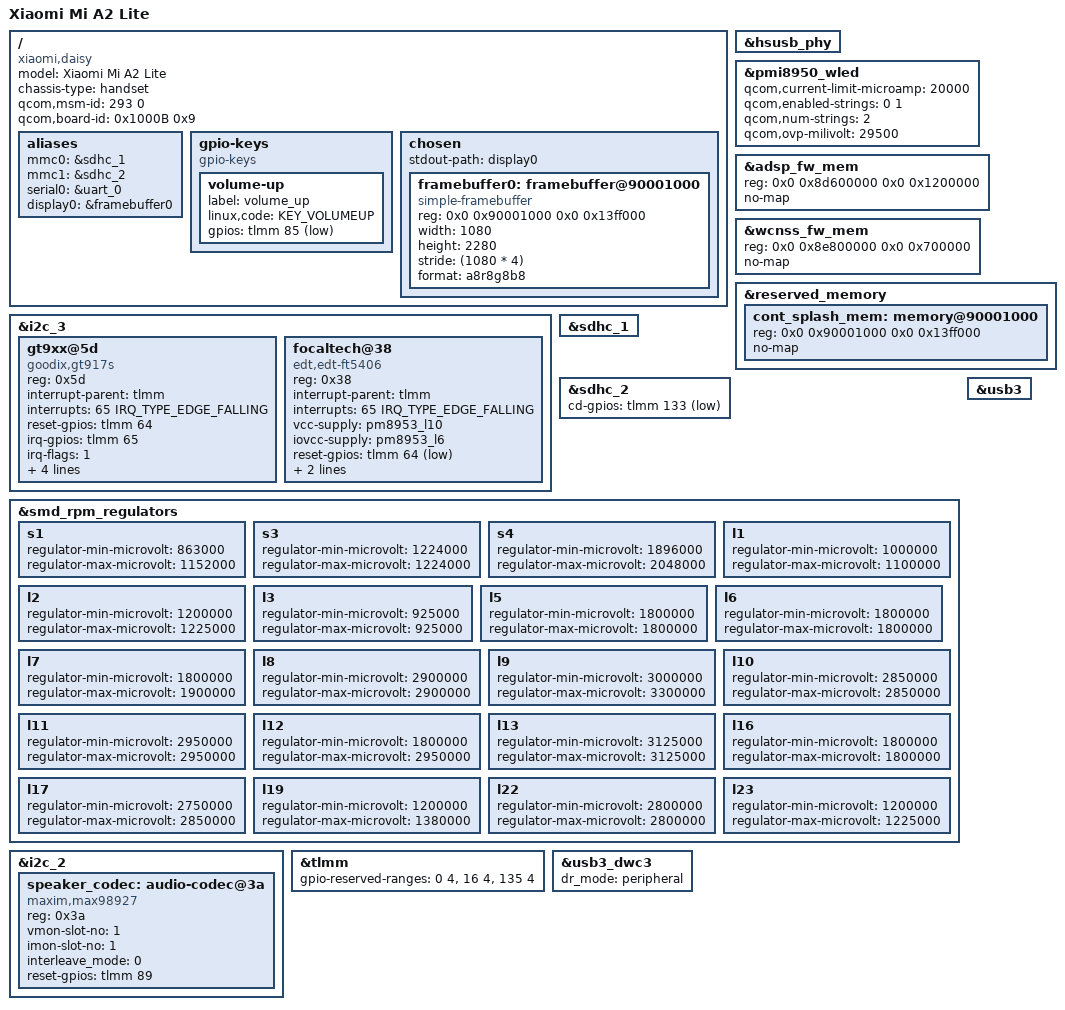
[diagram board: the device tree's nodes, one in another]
/* Copyright (c) 2017,2020 The Linux Foundation. All rights reserved.
 *
 * This program is free software; you can redistribute it and/or modify
 * it under the terms of the GNU General Public License version 2 and
 * only version 2 as published by the Free Software Foundation.
 *
 * This program is distributed in the hope that it will be useful,
 * but WITHOUT ANY WARRANTY; without even the implied warranty of
 * MERCHANTABILITY or FITNESS FOR A PARTICULAR PURPOSE.  See the
 * GNU General Public License for more details.
 */
/dts-v1/;

#include "msm8953-pm8953.dtsi"
#include "pmi8950.dtsi"
#include <dt-bindings/leds/common.h>
#include <dt-bindings/gpio/gpio.h>

/ {
	model = "Xiaomi Mi A2 Lite";
	compatible = "xiaomi,daisy", "qcom,msm8953";
	chassis-type = "handset";
	qcom,msm-id = <293 0>;
	qcom,board-id= <0x1000B 0x9>;

	aliases {
		mmc0 = &sdhc_1;
		mmc1 = &sdhc_2;
		serial0 = &uart_0;
		display0 = &framebuffer0;
	};

	gpio-keys {
		compatible = "gpio-keys";

		volume-up {
			label = "volume_up";
			linux,code = <KEY_VOLUMEUP>;
			gpios = <&tlmm 85 GPIO_ACTIVE_LOW>;
		};
	};

	chosen {
		stdout-path = "serial0:115200n8";
		#address-cells = <2>;
		#size-cells = <2>;
		ranges;

		stdout-path = "display0";
		framebuffer0: framebuffer@90001000 {
			compatible = "simple-framebuffer";
			reg = <0x0 0x90001000 0x0 0x13ff000>;
			width = <1080>;
			height = <2280>;
			stride = <(1080 * 4)>;
			format = "a8r8g8b8";
		};
	};

};

&hsusb_phy {
	status = "okay";
};

&i2c_3 {
	status = "okay";

	gt9xx@5d {
		compatible = "goodix,gt917s";
		reg = <0x5d>;

		interrupt-parent = <&tlmm>;
		interrupts = <65 IRQ_TYPE_EDGE_FALLING>;

		reset-gpios = <&tlmm 64 0x0>;
		irq-gpios = <&tlmm 65 0x2008>;
		irq-flags = <1>;

		AVDD28-supply = <&pm8953_l10>;
		VDDIO-supply = <&pm8953_l6>;

		touchscreen-size-x = <1080>;
		touchscreen-size-y = <2280>;
	};
	focaltech@38 {
		compatible = "edt,edt-ft5406", "edt,edt-ft5x06";
		reg = <0x38>;
		interrupt-parent = <&tlmm>;
		interrupts = <65 IRQ_TYPE_EDGE_FALLING>;
		vcc-supply = <&pm8953_l10>;
		iovcc-supply = <&pm8953_l6>;

		reset-gpios = <&tlmm 64 GPIO_ACTIVE_LOW>;

		touchscreen-size-x = <1080>;
		touchscreen-size-y = <2280>;
	};
};

&pmi8950_wled {
	status = "okay";

	qcom,current-limit-microamp = <20000>;
	qcom,enabled-strings = <0 1>;
	qcom,num-strings = <2>;
	qcom,ovp-milivolt = <29500>;
};

&adsp_fw_mem {
	reg = <0x0 0x8d600000 0x0 0x1200000>;
	no-map;
};

&wcnss_fw_mem {
	reg = <0x0 0x8e800000 0x0 0x700000>;
	no-map;
};

&reserved_memory {
	cont_splash_mem: memory@90001000 {
		reg = <0x0 0x90001000 0x0 0x13ff000>;
		no-map;
	};
};

&sdhc_1 {
	status = "okay";
};

&sdhc_2 {
	status = "okay";
	cd-gpios = <&tlmm 133 GPIO_ACTIVE_LOW>;
};

&smd_rpm_regulators {
	s1 {
		regulator-min-microvolt = <863000>;
		regulator-max-microvolt = <1152000>;
	};

	s3 {
		regulator-min-microvolt = <1224000>;
		regulator-max-microvolt = <1224000>;
	};

	s4 {
		regulator-min-microvolt = <1896000>;
		regulator-max-microvolt = <2048000>;
	};

	l1 {
		regulator-min-microvolt = <1000000>;
		regulator-max-microvolt = <1100000>;
	};

	l2 {
		regulator-min-microvolt = <1200000>;
		regulator-max-microvolt = <1225000>;
	};

	l3 {
		regulator-min-microvolt = <925000>;
		regulator-max-microvolt = <925000>;
	};

	l5 {
		regulator-min-microvolt = <1800000>;
		regulator-max-microvolt = <1800000>;
	};

	l6 {
		regulator-min-microvolt = <1800000>;
		regulator-max-microvolt = <1800000>;
	};

	l7 {
		regulator-min-microvolt = <1800000>;
		regulator-max-microvolt = <1900000>;
	};

	l8 {
		regulator-min-microvolt = <2900000>;
		regulator-max-microvolt = <2900000>;
	};

	l9 {
		regulator-min-microvolt = <3000000>;
		regulator-max-microvolt = <3300000>;
	};

	l10 {
		regulator-min-microvolt = <2850000>;
		regulator-max-microvolt = <2850000>;
	};

	l11 {
		regulator-min-microvolt = <2950000>;
		regulator-max-microvolt = <2950000>;
	};

	l12 {
		regulator-min-microvolt = <1800000>;
		regulator-max-microvolt = <2950000>;
	};

	l13 {
		regulator-min-microvolt = <3125000>;
		regulator-max-microvolt = <3125000>;
	};

	l16 {
		regulator-min-microvolt = <1800000>;
		regulator-max-microvolt = <1800000>;
	};

	l17 {
		regulator-min-microvolt = <2750000>;
		regulator-max-microvolt = <2850000>;
	};

	l19 {
		regulator-min-microvolt = <1200000>;
		regulator-max-microvolt = <1380000>;
	};

	l22 {
		regulator-min-microvolt = <2800000>;
		regulator-max-microvolt = <2800000>;
	};

	l23 {
		regulator-min-microvolt = <1200000>;
		regulator-max-microvolt = <1225000>;
	};
};

&i2c_2 {
	status = "okay";
	speaker_codec: audio-codec@3a {
		compatible = "maxim,max98927";
		status = "okay";
		reg = <0x3a>;
		vmon-slot-no = <1>;
		imon-slot-no = <1>;
		interleave_mode = <0>;
		#sound-dai-cells = <0>;

		reset-gpios = <&tlmm 89 0>;
	};
};

&tlmm {
	gpio-reserved-ranges = <0 4>, <16 4>, <135 4>;
};

&usb3 {
	status = "okay";
};

&usb3_dwc3 {
	dr_mode = "peripheral";
};
